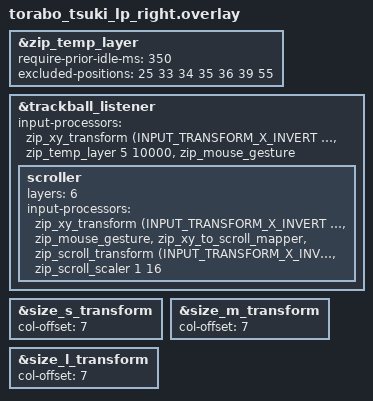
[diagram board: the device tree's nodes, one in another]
#include "torabo_tsuki_lp.dtsi"
#include <input/processors.dtsi>
#include <dt-bindings/zmk/input_transform.h>

#include <mouse-gesture.dtsi>

&zip_temp_layer {
    require-prior-idle-ms = <350>;
    excluded-positions = <
        25 // a
        33 // J
        34 // K
        35 // L
        36 // ;
        39 // Z
        55 // LCMD
    >;
};

&trackball_listener {
    input-processors = <
        &zip_xy_transform (INPUT_TRANSFORM_X_INVERT | INPUT_TRANSFORM_Y_INVERT)
        &zip_temp_layer 5 10000
        &zip_mouse_gesture
    >;
    scroller {
        layers = <6>;
        input-processors = <
            &zip_xy_transform (INPUT_TRANSFORM_X_INVERT | INPUT_TRANSFORM_Y_INVERT)
            &zip_mouse_gesture
            &zip_xy_to_scroll_mapper
            &zip_scroll_transform (INPUT_TRANSFORM_X_INVERT | INPUT_TRANSFORM_Y_INVERT)
            &zip_scroll_scaler 1 16
        >;
    };
};

&size_s_transform {
    col-offset = <7>;
};

&size_m_transform {
    col-offset = <7>;
};

&size_l_transform {
    col-offset = <7>;
};
